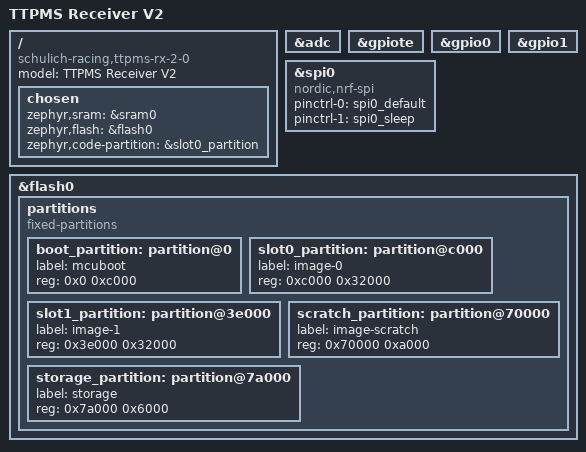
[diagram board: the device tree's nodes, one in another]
// Copyright (c) 2023 Nordic Semiconductor ASA
// SPDX-License-Identifier: Apache-2.0

/dts-v1/;
#include <nordic/nrf52833_qiaa.dtsi>
#include "ttpms_rx_2_0-pinctrl.dtsi"

/ {
	model = "TTPMS Receiver V2";
	compatible = "schulich-racing,ttpms-rx-2-0";

	chosen {
		zephyr,sram = &sram0;
		zephyr,flash = &flash0;
		zephyr,code-partition = &slot0_partition;
	};
};

&adc {
	status = "okay";
};

&gpiote {
	status = "okay";
};

&gpio0 {
	status = "okay";
};

&gpio1 {
	status = "okay";
};

&spi0 {
	compatible = "nordic,nrf-spi";
	status = "okay";
	pinctrl-0 = <&spi0_default>;
	pinctrl-1 = <&spi0_sleep>;
	pinctrl-names = "default", "sleep";
};

&flash0 {
	partitions {
		compatible = "fixed-partitions";
		#address-cells = <1>;
		#size-cells = <1>;

		boot_partition: partition@0 {
			label = "mcuboot";
			reg = <0x0 0xc000>;
		};
		slot0_partition: partition@c000 {
			label = "image-0";
			reg = <0xc000 0x32000>;
		};
		slot1_partition: partition@3e000 {
			label = "image-1";
			reg = <0x3e000 0x32000>;
		};
		scratch_partition: partition@70000 {
			label = "image-scratch";
			reg = <0x70000 0xa000>;
		};
		storage_partition: partition@7a000 {
			label = "storage";
			reg = <0x7a000 0x6000>;
		};
	};
};

